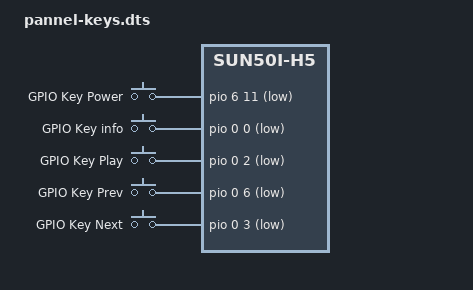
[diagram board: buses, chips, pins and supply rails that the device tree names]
/dts-v1/;
/plugin/;

/ {
	compatible = "allwinner,sun8i-h3", "allwinner,sun4i-a10", "allwinner,sun7i-a20", "allwinner,sun50i-a64", "allwinner,sun50i-h5";

	/*
	 * This fragment is needed only for the internal pull-up activation,
	 * external pull-up resistor is highly recommended if using long wires
	 */
	fragment@0 {
		target = <&pio>;
		__overlay__ {
			gpio_button_0: gpio_button_0 {
				pins = "PG11","PA6", "PA3", "PA2", "PA0";
				function = "gpio_in";
				bias-pull-up;
			};
		};
	};

	fragment@1 {
		target-path = "/";
		__overlay__ {
			gpio-keys-user {
				/*
				 * Use "gpio-keys" for EINT capable pins, "gpio-keys-polled" for other pins
				 * add "poll-interval" property if using "gpio-keys-polled"
				 */
				compatible = "gpio-keys";
				pinctrl-names = "default";
				pinctrl-0 = <&gpio_button_0>;

				power_button {
					label = "GPIO Key Power";
					linux,code = <59>; /* KEY_F1, see include/uapi/linux/input-event-codes.h */
					gpios = <&pio 6 11 1>; /* PG11 GPIO_ACTIVE_LOW */
				};

				info_button {
					label = "GPIO Key info";
					linux,code = <60>; /* KEY_F2, see include/uapi/linux/input-event-codes.h */
					gpios = <&pio 0 0 1>; /* PA0 GPIO_ACTIVE_LOW */
				};
				play_button {
					label = "GPIO Key Play";
					linux,code = <61>; /* KEY_F3, see include/uapi/linux/input-event-codes.h */
					gpios = <&pio 0 2 1>; /* PA2 GPIO_ACTIVE_LOW */
				};
				prev_button {
					label = "GPIO Key Prev";
					linux,code = <62>; /* KEY_F4, see include/uapi/linux/input-event-codes.h */
					gpios = <&pio 0 6 1>; /* PA6 GPIO_ACTIVE_LOW */
				};
				next_button {
					label = "GPIO Key Next";
					linux,code = <63>; /* KEY_F5, see include/uapi/linux/input-event-codes.h */
					gpios = <&pio 0 3 1>; /* PA3 GPIO_ACTIVE_LOW */
				};
			};

		};
	};
};

